VERSION ""

NS_ :

BS_:

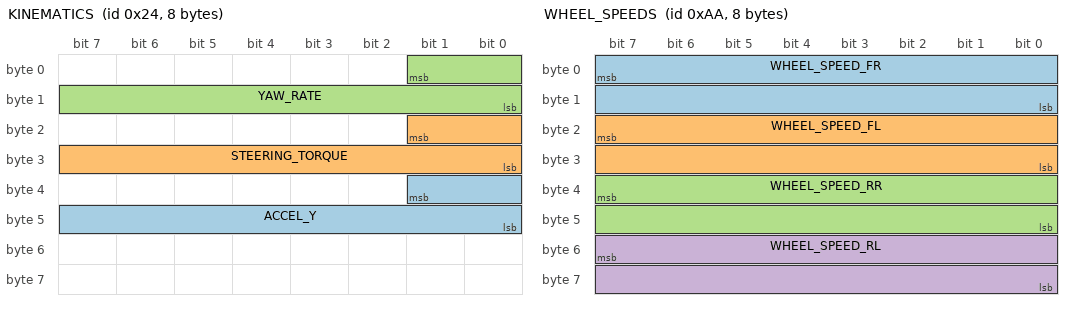
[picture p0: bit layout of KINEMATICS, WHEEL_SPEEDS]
BO_ 36 KINEMATICS: 8 XXX
 SG_ ACCEL_Y : 33|10@0+ (1,-512) [0|65535] "" XXX
 SG_ STEERING_TORQUE : 17|10@0+ (1,-512) [0|65535] "" XXX
 SG_ YAW_RATE : 1|10@0+ (1,-512) [0|65535] "" XXX

BO_ 166 BRAKE: 8 XXX
 SG_ BRAKE_AMOUNT : 7|8@0+ (1,0) [0|255] "" XXX
 SG_ BRAKE_PEDAL : 23|8@0+ (1,0) [0|255] "" XXX

BO_ 170 WHEEL_SPEEDS: 8 XXX
 SG_ WHEEL_SPEED_FR : 7|16@0+ (0.0062,-67.67) [0|250] "mph" XXX
 SG_ WHEEL_SPEED_FL : 23|16@0+ (0.0062,-67.67) [0|250] "mph" XXX
 SG_ WHEEL_SPEED_RR : 39|16@0+ (0.0062,-67.67) [0|250] "mph" XXX
 SG_ WHEEL_SPEED_RL : 55|16@0+ (0.0062,-67.67) [0|250] "mph" XXX

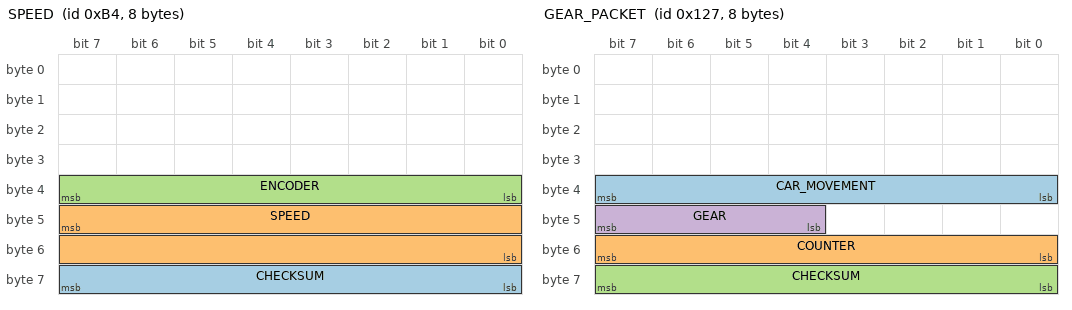
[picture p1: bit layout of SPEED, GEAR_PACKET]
BO_ 180 SPEED: 8 XXX
 SG_ CHECKSUM : 63|8@0+ (1,0) [0|255] "" XXX
 SG_ SPEED : 47|16@0+ (0.0062,0) [0|115] "mph" XXX
 SG_ ENCODER : 39|8@0+ (1,0) [0|255] "" XXX

BO_ 295 GEAR_PACKET: 8 XXX
 SG_ CAR_MOVEMENT : 39|8@0- (1,0) [0|255] "" XXX
 SG_ COUNTER : 55|8@0+ (1,0) [0|255] "" XXX
 SG_ CHECKSUM : 63|8@0+ (1,0) [0|255] "" XXX
 SG_ GEAR : 47|4@0+ (1,0) [0|15] "" XXX

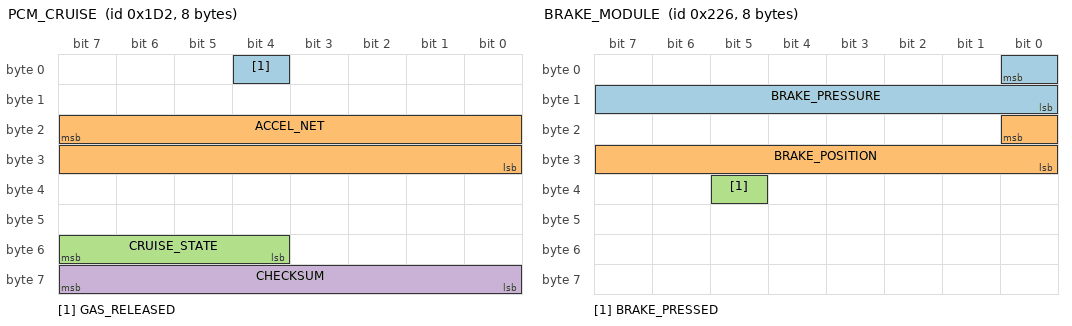
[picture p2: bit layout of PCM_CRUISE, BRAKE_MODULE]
BO_ 466 PCM_CRUISE: 8 XXX
 SG_ GAS_RELEASED : 4|1@0+ (1,0) [0|1] "" XXX
 SG_ ACCEL_NET : 23|16@0- (0.001,0) [-20|20] "m/s2" XXX
 SG_ CRUISE_STATE : 55|4@0+ (1,0) [0|15] "" XXX
 SG_ CHECKSUM : 63|8@0+ (1,0) [0|255] "" XXX

BO_ 550 BRAKE_MODULE: 8 XXX
 SG_ BRAKE_PRESSURE : 0|9@0+ (1,0) [0|511] "" XXX
 SG_ BRAKE_POSITION : 16|9@0+ (1,0) [0|511] "" XXX
 SG_ BRAKE_PRESSED : 37|1@0+ (1,0) [0|1] "" XXX

BO_ 552 ACCELEROMETER: 8 XXX
 SG_ ACCEL_Z : 22|15@0- (1,0) [0|32767] "" XXX
 SG_ ACCEL_X : 6|15@0- (0.001,0) [-20|20] "m/s2" XXX

BO_ 560 BRAKE_MODULE2: 8 XXX
 SG_ BRAKE_LIGHTS : 26|1@0+ (1,0) [0|1] "" XXX

BO_ 581 GAS_PEDAL: 8 XXX
 SG_ GAS_PEDAL : 23|8@0+ (0.005,0) [0|1] "" XXX

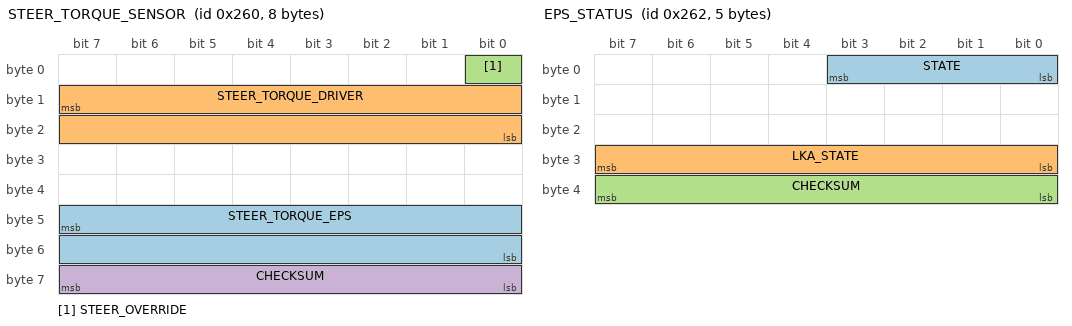
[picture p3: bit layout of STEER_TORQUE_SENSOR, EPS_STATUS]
BO_ 608 STEER_TORQUE_SENSOR: 8 XXX
 SG_ STEER_TORQUE_EPS : 47|16@0- (0.66,0) [-20000|20000] "" XXX
 SG_ STEER_TORQUE_DRIVER : 15|16@0- (1,0) [-32768|32767] "" XXX
 SG_ STEER_OVERRIDE : 0|1@0+ (1,0) [0|1] "" XXX
 SG_ CHECKSUM : 63|8@0+ (1,0) [0|255] "" XXX

BO_ 610 EPS_STATUS: 5 EPS
 SG_ STATE : 3|4@0+ (1,0) [0|15] "" XXX
 SG_ LKA_STATE : 31|8@0+ (1,0) [0|255] "" XXX
 SG_ CHECKSUM : 39|8@0+ (1,0) [0|255] "" XXX

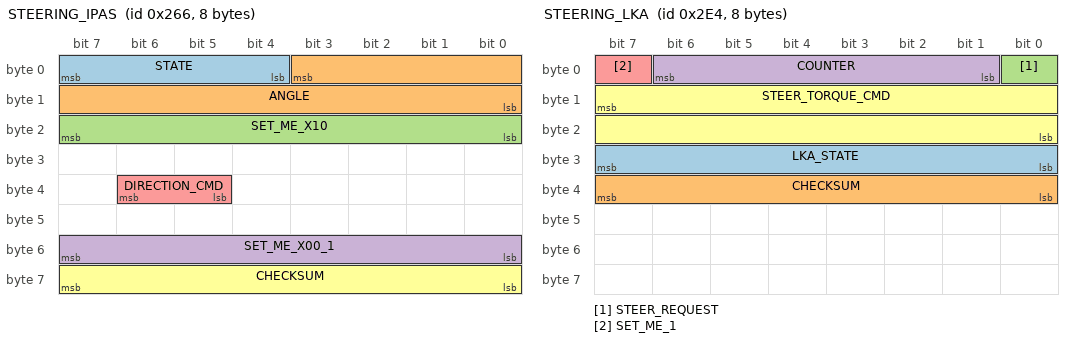
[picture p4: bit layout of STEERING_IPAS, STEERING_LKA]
BO_ 614 STEERING_IPAS: 8 IPAS
 SG_ STATE : 7|4@0+ (1,0) [0|15] "" XXX
 SG_ ANGLE : 3|12@0- (1,0) [0|16777215] "" XXX
 SG_ SET_ME_X10 : 23|8@0+ (1,0) [0|255] "" XXX
 SG_ SET_ME_X00_1 : 55|8@0+ (1,0) [0|255] "" XXX
 SG_ DIRECTION_CMD : 38|2@0+ (1,0) [0|3] "" XXX
 SG_ CHECKSUM : 63|8@0+ (1,0) [0|255] "" XXX

BO_ 643 PRE_COLLISION: 8 XXX

BO_ 740 STEERING_LKA: 8 XXX
 SG_ LKA_STATE : 31|8@0+ (1,0) [0|255] "" XXX
 SG_ CHECKSUM : 39|8@0+ (1,0) [0|255] "" XXX
 SG_ STEER_REQUEST : 0|1@0+ (1,0) [0|1] "" XXX
 SG_ COUNTER : 6|6@0+ (1,0) [0|63] "" XXX
 SG_ SET_ME_1 : 7|1@0+ (1,0) [0|1] "" XXX
 SG_ STEER_TORQUE_CMD : 15|16@0- (1,0) [0|65535] "" XXX

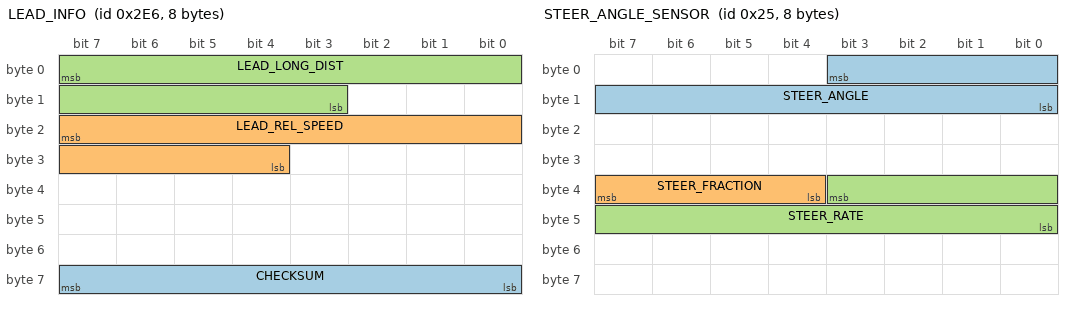
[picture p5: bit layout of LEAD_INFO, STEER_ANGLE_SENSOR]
BO_ 742 LEAD_INFO: 8 DSU
 SG_ CHECKSUM : 63|8@0+ (1,0) [0|255] "" HCU
 SG_ LEAD_REL_SPEED : 23|12@0- (0.025,0) [-100|100] "m/s" HCU
 SG_ LEAD_LONG_DIST : 7|13@0+ (0.05,0) [0|300] "m" HCU

BO_ 835 ACC_CONTROL: 8 DSU
 SG_ ACCEL_CMD : 7|16@0- (0.001,0) [-20|20] "m/s2" HCU

BO_ 1556 STEERING_LEVERS: 8 XXX
 SG_ TURN_SIGNALS : 29|2@0+ (1,0) [0|3] "" XXX

BO_ 37 STEER_ANGLE_SENSOR: 8 XXX
 SG_ STEER_ANGLE : 3|12@0- (1.5,0) [-500|500] "deg" XXX
 SG_ STEER_FRACTION : 39|4@0- (0.1,0) [-0.7|0.7] "deg" XXX
 SG_ STEER_RATE : 35|12@0- (1,0) [-2000|2000] "deg/s" XXX

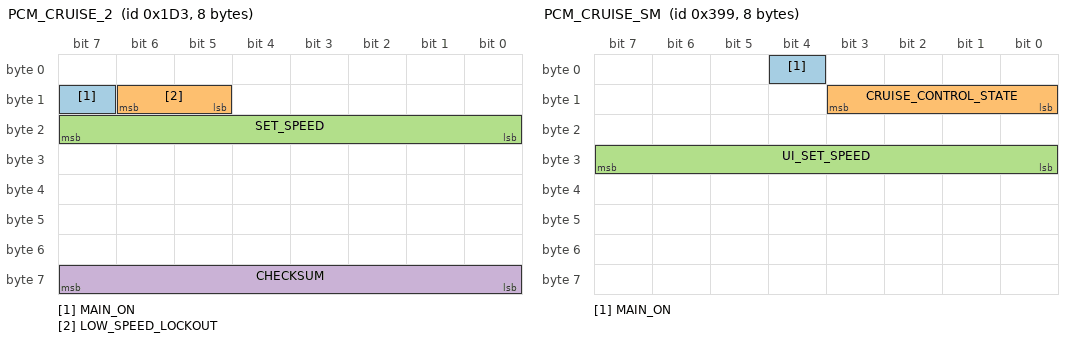
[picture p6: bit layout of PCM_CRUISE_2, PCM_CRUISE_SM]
BO_ 467 PCM_CRUISE_2: 8 XXX
 SG_ MAIN_ON : 15|1@0+ (1,0) [0|1] "" XXX
 SG_ LOW_SPEED_LOCKOUT : 14|2@0+ (1,0) [0|3] "kph" XXX
 SG_ SET_SPEED : 23|8@0+ (1,0) [0|255] "kph" XXX
 SG_ CHECKSUM : 63|8@0+ (1,0) [0|255] "" XXX

BO_ 921 PCM_CRUISE_SM: 8 XXX
 SG_ MAIN_ON : 4|1@0+ (1,0) [0|1] "" XXX
 SG_ CRUISE_CONTROL_STATE : 11|4@0+ (1,0) [0|15] "" XXX
 SG_ UI_SET_SPEED : 31|8@0+ (1,0) [0|255] "" XXX

BO_ 951 ESP_CONTROL: 8 ESP
 SG_ TC_DISABLED : 13|1@0+ (1,0) [0|1] "" XXX

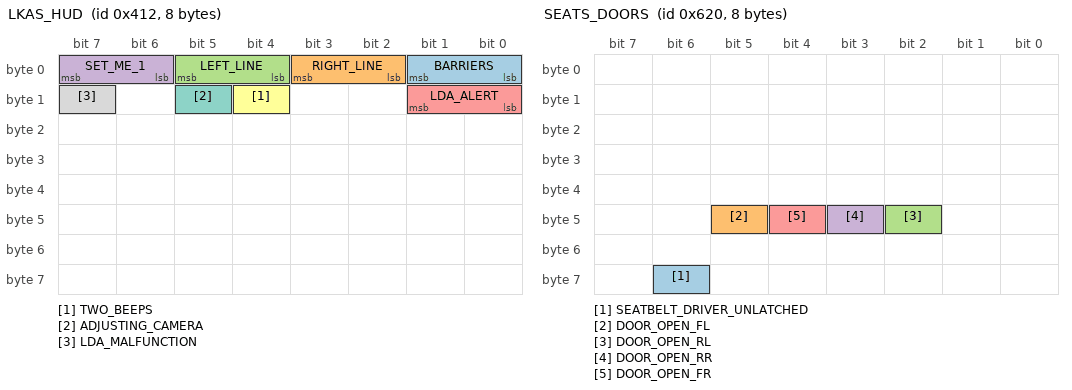
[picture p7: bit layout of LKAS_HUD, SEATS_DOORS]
BO_ 1042 LKAS_HUD: 8 XXX
 SG_ BARRIERS : 1|2@0+ (1,0) [0|3] "" XXX
 SG_ RIGHT_LINE : 3|2@0+ (1,0) [0|3] "" XXX
 SG_ LEFT_LINE : 5|2@0+ (1,0) [0|3] "" XXX
 SG_ SET_ME_1 : 7|2@0+ (1,0) [0|3] "" XXX
 SG_ LDA_ALERT : 9|2@0+ (1,0) [0|3] "" XXX
 SG_ TWO_BEEPS : 12|1@0+ (1,0) [0|1] "" XXX
 SG_ ADJUSTING_CAMERA : 13|1@0+ (1,0) [0|1] "" XXX
 SG_ LDA_MALFUNCTION : 15|1@0+ (1,0) [0|1] "" XXX

BO_ 1553 UI_SEETING: 8 XXX
 SG_ UNITS : 26|2@0+ (1,0) [0|3] "" XXX

BO_ 1568 SEATS_DOORS: 8 XXX
 SG_ SEATBELT_DRIVER_UNLATCHED : 62|1@0+ (1,0) [0|1] "" XXX
 SG_ DOOR_OPEN_FL : 45|1@0+ (1,0) [0|1] "" XXX
 SG_ DOOR_OPEN_RL : 42|1@0+ (1,0) [0|1] "" XXX
 SG_ DOOR_OPEN_RR : 43|1@0+ (1,0) [0|1] "" XXX
 SG_ DOOR_OPEN_FR : 44|1@0+ (1,0) [0|1] "" XXX

BO_ 452 POWERTRAIN: 8 XXX
 SG_ ENGINE_RPM : 7|16@0+ (1,0) [0|65535] "rpm" XXX
 SG_ CHECKSUM : 63|8@0+ (1,0) [0|255] "" XXX

BU_: XXX

CM_ "AUTOGENERATED FILE, DO NOT EDIT";

CM_ "Imported file _comma.dbc starts here";
CM_ "BO_ STEERING_IPAS_COMMA: Copy of msg 614 so we can do angle control while the Park Assist ECU is connected (Panda spoofs 614 with 359 on connector J70). Note that addresses 0x266 and 0x167 are checksum-invariant";

CM_ "BO_ SECONDARY_STEER_ANGLE: ZSS is a high-precision steering angle sensor that can replace the lower resolution sensor in most TSS1 Toyotas. Learn more: https://github.com/commaai/openpilot/wiki/Toyota-Lexus#zorro-steering-sensor-zss";

CM_ "BO_ SDSU: The sDSU is a modified DSU for use in TSS1 Toyotas. Learn more: https://github.com/wocsor/panda/tree/smart_dsu";
CM_ SG_ 767 FD_BUTTON "The follow distance button signal as forwarded by the sdsu";

CM_ "Imported file _toyota_2017.dbc starts here";
CM_ SG_ 36 YAW_RATE "verify";
CM_ SG_ 36 ACCEL_X "x-axis accel";
CM_ SG_ 37 STEER_FRACTION "1/15th of the signal STEER_ANGLE, which is 1.5 deg; note that 0x8 is never set";
CM_ SG_ 37 STEER_RATE "factor is tbd";
CM_ SG_ 466 NEUTRAL_FORCE "force in newtons the engine/electric motors are applying without any acceleration commands or user input";
CM_ SG_ 466 ACC_BRAKING "whether brakes are being actuated from ACC command";
CM_ SG_ 466 ACCEL_NET "net acceleration produced by the system, given ACCEL_CMD, road grade and other factors";
CM_ SG_ 466 CRUISE_STATE "Active state is 8, if standstill is requested will switch to state 11(3 sec timer), after timer is elapsed will switch into state 7(standstill). If plus button was pressed - status 9, minus button pressed - status 10";
CM_ SG_ 467 ACC_FAULTED "1 when ACC is faulted and the PCM disallows engagement";
CM_ SG_ 467 SET_SPEED "43 km/h are shown as 28 mph, so conversion isn't perfect";
CM_ SG_ 467 LOW_SPEED_LOCKOUT "in low speed lockout, system would always disengage below 28mph";
CM_ SG_ 560 BRAKE_PRESSED "another brake pressed?";
CM_ SG_ 581 GAS_PEDAL "it seems slightly filtered";
CM_ SG_ 608 STEER_TORQUE_DRIVER "driver torque";
CM_ SG_ 608 STEER_OVERRIDE "set when driver torque exceeds a certain value";
CM_ SG_ 614 ANGLE "set to measured angle when ipas control isn't active";
CM_ SG_ 643 _COUNTER "only used on cars that use this msg for cruise control";
CM_ SG_ 643 BRAKE_STATUS "only used on cars that use this msg for cruise control";
CM_ SG_ 643 PRECOLLISION_ACTIVE "set 0.5s before any braking";
CM_ SG_ 835 ACC_TYPE "if 2, car is likely to have a permanent low speed lockout. 1 is ok";
CM_ SG_ 835 RADAR_DIRTY "Display Clean Radar Sensor message on HUD";
CM_ SG_ 835 ACC_MALFUNCTION "display ACC fault on dash if set to 1";
CM_ SG_ 835 ACC_CUT_IN "Display blinking yellow lead if set to 1";
CM_ SG_ 835 DISTANCE "Cycle through ACC following distance from long, mid, short when set to 1";
CM_ SG_ 835 ITS_CONNECT_LEAD "Displayed when lead car is capable of ITS Connect";
CM_ SG_ 835 ALLOW_LONG_PRESS "Enable Toyota's factory set speed increment behaviour, available on both metrics cars and imperial unit cars";
CM_ SG_ 835 PERMIT_BRAKING "Original ACC has this going high when a car in front is detected. In openpilot and before the PERMIT_BRAKING name, this was 'SET_ME_1' and is hardcoded to be high. Unsure if only informational or has an effect though existing usage in openpilot is to always set it to 1. Originally 'PMTBRKG' in the leaked toyota_2017_ref_pt.dbc file and name expansion speculated to be PerMiT BRaKinG.";
CM_ SG_ 835 ACCEL_CMD_ALT "Copy of main ACCEL_CMD, but across 8 bits instead of 16 bits like ACCEL_CMD. Unsure if only informational or has an effect. Likely informational as existing openpilot sets this to 0 and no loss of functionality observed. Originally 'AT_RAW' in leaked toyota_2017_ref_pt.dbc file.";
CM_ SG_ 865 GAS_PEDAL_ALT "copy of main GAS_PEDAL. Both use 8 bits. Might indicate that this message is for pedals.";
CM_ SG_ 865 CLUTCH_RELEASED "boolean of clutch for 6MT.";
CM_ SG_ 865 ACC_FAULTED "1 when ACC is faulted and the PCM disallows engagement. Also describes a lockout when the ACC_CONTROL->ACC_MALFUNCTION bit is set.";
CM_ SG_ 921 UI_SET_SPEED "set speed shown in the vehicle's UI with the vehicle's unit";
CM_ SG_ 921 TEMP_ACC_FAULTED "1 when the UI is displaying or playing fault-related alerts or sounds. Also 1 when pressing main on.";
CM_ SG_ 951 BRAKE_LIGHTS_ACC "brake lights when ACC commands decel";
CM_ SG_ 956 GEAR "on 6MT, only R shows.";
CM_ SG_ 1009 UI_SET_SPEED "units seem to be whatever the car is set to";
CM_ SG_ 1041 PCS_INDICATOR "Pre-Collision System Indicator";
CM_ SG_ 1041 PCS_SENSITIVITY "Pre-Collision System Sensitivity";
CM_ SG_ 1041 PCS_DUST "alert: Front Camera Low Visibility Unavailable See Owner's Manual";
CM_ SG_ 1041 PCS_DUST2 "alert: Pre-Collision System Radar Sensor Blocked Unavailable Clean Radar Sensor";
CM_ SG_ 1041 PCS_TEMP "alert: Front Camera Out of Temperature Range Unavailable Wait until Normal Temperature";
CM_ SG_ 1041 PCS_TEMP2 "alert: Pre-Collision System Out of Temperature Range Unavailable See Owner's Manual";
CM_ SG_ 1041 FRD_ADJ "alert: ERROR ADJUSTING FRONT RADAR BEAM";
CM_ SG_ 1042 LDA_SA_TOGGLE "LDA Steering Assist Toggle";
CM_ SG_ 1042 LDW_EXIST "Unclear what this is, it's usually set to 0";
CM_ SG_ 1042 LDA_SENSITIVITY "LDA Sensitivity";
CM_ SG_ 1042 LDA_ON_MESSAGE "Display LDA Turned ON message";
CM_ SG_ 1042 REPEATED_BEEPS "LDA audible warning";
CM_ SG_ 1042 LDA_UNAVAILABLE_QUIET "LDA toggles and sensitivity settings are greyed out if set to 1";
CM_ SG_ 1042 LDA_MESSAGES "Various LDA Messages";
CM_ SG_ 1042 LDA_FRONT_CAMERA_BLOCKED "originally LDAFCVB, LDA related settings are greyed out if set to 1";
CM_ SG_ 1042 TAKE_CONTROL "Please Control Steering Wheel warning";
CM_ SG_ 1042 LANE_SWAY_TOGGLE "Lane Sway Warning System SWS Switch";
CM_ SG_ 1042 LANE_SWAY_WARNING "Lane Sway Warning System Triggered";
CM_ SG_ 1042 LANE_SWAY_FLD "Unknown signal for Lane Sway Warning System, set to 7 on stock system when SWS is enabled, 0 when SWS is disabled";
CM_ SG_ 1042 LANE_SWAY_BUZZER "Similar to TWO_BEEPS";
CM_ SG_ 1042 SET_ME_X01 "empty bit on leaked dbc, always set to 1 during normal operations";
CM_ SG_ 1042 SET_ME_X02 "empty bit on leaked dbc, always set to 2 during normal operations";
CM_ SG_ 1083 STATE "when the dashboard button is pressed, the value changes from zero to non-zero";
CM_ SG_ 1161 SPDVAL1 "Numbers 0-199 is displayed, 200-254 displays circle without number and 255 is for no limit.";
CM_ SG_ 1161 SYNCID1 "counter from 1 to f at 1 Hz";
CM_ SG_ 1161 SPDVAL2 "conditional speed value 70";
CM_ SG_ 1162 SGNNUMP "1 if SPDVAL1 is set, otherwise 0";
CM_ SG_ 1162 SYNCID2 "counter from 1 to f at 1 Hz";
CM_ SG_ 1163 TSREQPD "always 1";
CM_ SG_ 1163 TSRMSW "always 1";
CM_ SG_ 1163 OTSGNNTM "always 3";
CM_ SG_ 1163 NTLVLSPD "always 3";
CM_ SG_ 1163 OVSPNTM "always 3";
CM_ SG_ 1163 OVSPVALL "-5 at start then 2 after 2 seconds";
CM_ SG_ 1163 OVSPVALM "-5 at start then 5 after 2 seconds";
CM_ SG_ 1163 OVSPVALH "-5 at start then 10 after 2 seconds";
CM_ SG_ 1163 TSRSPU "always 1";
CM_ SG_ 1552 UI_SPEED "Does not appear to match dash";
CM_ SG_ 1552 METER_SLIDER_BRIGHTNESS_PCT "Combination display brightness setting, scales from 12 per cent to 100 per cent, reflects combination meter settings only, not linked with headlight state";
CM_ SG_ 1552 METER_SLIDER_LOW_BRIGHTNESS "Combination display low brightness mode, also controls footwell lighting";
CM_ SG_ 1552 METER_SLIDER_DIMMED "Combination display slider not at max, reflects combination meter settings only, not linked with headlight state";
CM_ SG_ 1553 ODOMETER "Unit is dependent upon units signal";
CM_ SG_ 1592 LOCK_STATUS_CHANGED "1 on rising edge of lock/unlocking";
CM_ SG_ 1592 LOCK_STATUS "The next 3 bits always seem to follow this signal.";
CM_ SG_ 1592 LOCKED_VIA_KEYFOB "1 for as long as car is locked with key fob or door handle touch";

CM_ "toyota_new_mc_pt.dbc starts here";

CM_ SG_ 548 BRAKE_PRESSURE "seems prop to pedal force";
CM_ SG_ 548 BRAKE_POSITION "seems proportional to pedal displacement, unclear the max value of 0x1c8";
CM_ SG_ 610 TYPE "seems 1 on Corolla, 0 on all others";

VAL_ 368 Gear_State 4 "D" 2 "N" 1 "R" 0 "P" ;

VAL_ 501 CRUISE_STATE 0 "Off" 1 "CC On" 2 "CC Engaged" 3 "ACC On" 4 "ACC Engaged";
VAL_ 746 PRNDL 5 "L" 4 "D" 3 "N" 2 "R" 1 "P";
